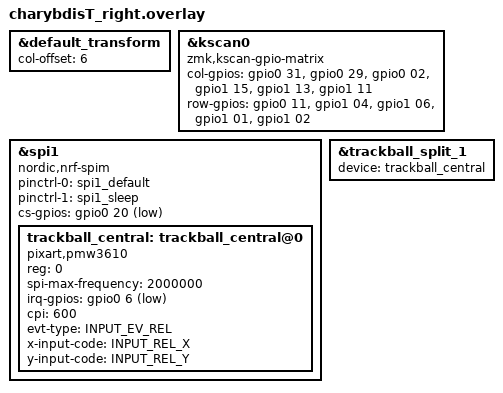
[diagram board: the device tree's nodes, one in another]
#include "charybdisT.dtsi"
#include "charybdisT_pmw3610.dtsi"
#include "common_keyboard.dtsi"
#include "split_input_common.dtsi"
&default_transform {
    col-offset = <6>;
};
&kscan0 {
    compatible = "zmk,kscan-gpio-matrix";
    col-gpios
        = <&gpio0 31 GPIO_ACTIVE_HIGH>
        , <&gpio0 29 GPIO_ACTIVE_HIGH>
        , <&gpio0 02 GPIO_ACTIVE_HIGH>
        , <&gpio1 15 GPIO_ACTIVE_HIGH>
        , <&gpio1 13 GPIO_ACTIVE_HIGH>
        , <&gpio1 11 GPIO_ACTIVE_HIGH>
        ;
    

    row-gpios
        = <&gpio0 11 (GPIO_ACTIVE_HIGH | GPIO_PULL_DOWN)>
        , <&gpio1 04 (GPIO_ACTIVE_HIGH | GPIO_PULL_DOWN)>
        , <&gpio1 06 (GPIO_ACTIVE_HIGH | GPIO_PULL_DOWN)>
        , <&gpio1 01 (GPIO_ACTIVE_HIGH | GPIO_PULL_DOWN)>
        , <&gpio1 02 (GPIO_ACTIVE_HIGH | GPIO_PULL_DOWN)>
        ;
};
// https://github.com/badjeff/zmk-pmw3610-driver
// &spi1 {
//   status = "okay";
// };

// &trackball {
//   status = "okay";
// };

// / {
//   trackball_listener {
//     compatible = "zmk,input-listener";
//     device = <&trackball>;

//   };
// };



#include <zephyr/dt-bindings/input/input-event-codes.h>
&spi1 {
    status = "okay";
    compatible = "nordic,nrf-spim";
    pinctrl-0 = <&spi1_default>;
    pinctrl-1 = <&spi1_sleep>;
    pinctrl-names = "default", "sleep";
    cs-gpios = <&gpio0 20 GPIO_ACTIVE_LOW>;

    trackball_central: trackball_central@0 {
        status = "okay";
        compatible = "pixart,pmw3610";
        reg = <0>;
        spi-max-frequency = <2000000>;
        irq-gpios = <&gpio0 6 (GPIO_ACTIVE_LOW | GPIO_PULL_UP)>;
        cpi = <600>;
        evt-type = <INPUT_EV_REL>;
        x-input-code = <INPUT_REL_X>;
        y-input-code = <INPUT_REL_Y>;
    };
};
&trackball_split_1 {
    status = "okay";
    device = <&trackball_central>;
};
